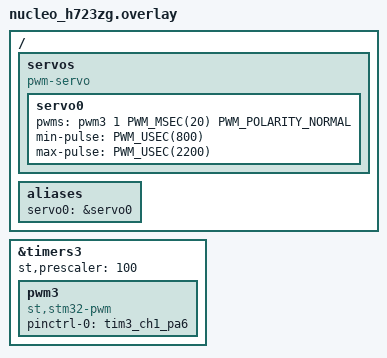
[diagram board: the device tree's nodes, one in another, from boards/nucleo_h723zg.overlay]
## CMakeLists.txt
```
cmake_minimum_required(VERSION 3.20.0)

set(CMAKE_CXX_STANDARD 11)
set(CMAKE_C_STANDARD 11)

# For the compile_commands.json file
set(CMAKE_EXPORT_COMPILE_COMMANDS ON)

# Set the Kconfig file
set(CONF_FILE "prj.conf")

find_package(Zephyr REQUIRED HINTS $ENV{ZEPHYR_BASE})
project(test)

add_subdirectory(${CMAKE_CURRENT_SOURCE_DIR}/lib/drivetrain)

target_sources(app PRIVATE ${CMAKE_CURRENT_SOURCE_DIR}/src/main.c)
```

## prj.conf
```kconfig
# Periphirals
CONFIG_PWM=y
CONFIG_SHELL=y

# CONFIG_PRINTK=y
# CONFIG_STDOUT_CONSOLE=y

# Logging
CONFIG_LOG=y
CONFIG_LOG_MODE_IMMEDIATE=y
CONFIG_LOG_DEFAULT_LEVEL=3
# CONFIG_PWM_LOG_LEVEL_DBG=y
# CONFIG_LOG_PRINTK=y

# Disable optimizations for debugging
CONFIG_DEBUG_OPTIMIZATIONS=y

# Thread aware debugging
CONFIG_THREAD_NAME=y
CONFIG_SEGGER_SYSTEMVIEW=y
CONFIG_USE_SEGGER_RTT=y
CONFIG_TRACING=y
CONFIG_DEBUG_THREAD_INFO=y
CONFIG_DEBUG_INFO=y

# Enable for post-mortem tracing
# NOTE: Recent versions of SEGGER Systemview come with incomplete API translation table for Zephyr
# To fix it: cp ZEPHYR_BASE/subsys/tracing/sysview/SYSVIEW_Zephyr.txt ~/.config/SEGGER/
CONFIG_SEGGER_SYSVIEW_POST_MORTEM_MODE=y
```

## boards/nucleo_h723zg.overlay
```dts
/ {
	servos {
		compatible = "pwm-servo";
		servo0: servo0 {
			pwms = <&pwm3 1 PWM_MSEC(20) PWM_POLARITY_NORMAL>;
			min-pulse = <PWM_USEC(800)>;
			max-pulse = <PWM_USEC(2200)>;
		};
	};

	aliases {
		servo0 = &servo0;
	};
};

&timers3 {
	status = "okay";
	// Timer at 275 MHz.
	st,prescaler = <100>;

	pwm3: pwm3 {
		compatible = "st,stm32-pwm";
		status = "okay";
		#pwm-cells = <0x3>;
		pinctrl-0 = <&tim3_ch1_pa6>;
		pinctrl-names = "default";
	};
};
```

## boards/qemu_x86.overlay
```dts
/ {
	pwmleds {
		compatible = "pwm-leds";

		red_pwm_led: red_pwm_led {
			pwms = <&pwm12 1 PWM_MSEC(20) PWM_POLARITY_NORMAL>;
			label = "User LD3 - PWM12";
		};
	};

    aliases {
        pwm-led0 = &red_pwm_led;
    };
};

&timers12 {
	st,prescaler = <10000>;
	status = "okay";

	pwm12: pwm {
		status = "okay";
		pinctrl-0 = <&tim12_ch1_pb14>;
		pinctrl-names = "default";
	};
};
```

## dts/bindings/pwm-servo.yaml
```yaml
description: |
  General Servo Motor PWM Bindings

compatible: pwm-servo

child-binding:
  description: PWM child node
  properties:
    pwms:
      required: true
      type: phandle-array

    min-pulse:
      type: int
      default: 800
      description: |
        Minimum pulse width in microseconds. This is the pulse width
        corresponding to the minimum servo position.

    max-pulse:
      type: int
      default: 2200
      description: |
        Maximum pulse width in microseconds. This is the pulse width
        corresponding to the maximum servo position.
```

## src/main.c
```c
// Copyright 2023 Jasper Jonker
#include <zephyr/kernel.h>
#include <zephyr/sys/printk.h>
#include <zephyr/device.h>
#include <zephyr/drivers/pwm.h>
#include <zephyr/drivers/uart.h>
#include <zephyr/logging/log.h>
#include "../lib/drivetrain/drivetrain.h"

/* LOG Module */
LOG_MODULE_REGISTER(main);

/* Function prototypes */
int8_t init_pwm_led(uint32_t period, uint32_t pulse_width);

/* PWM LED */
static const struct pwm_dt_spec pwm_led0 = PWM_DT_SPEC_GET(DT_ALIAS(pwm_led0));

// ------------------------------------------------
// Initialize PWM LED
// ------------------------------------------------
int8_t init_pwm_led(uint32_t period, uint32_t pulse_width) {
    if (!device_is_ready(pwm_led0.dev)) {
        LOG_ERR("Cannot find PWM LED device!\n");
        return -1;
    } else {
        LOG_INF("PWM LED device found: %s\r\n", pwm_led0.dev->name);
    }

    int ret = pwm_set_dt(&pwm_led0, period, pulse_width);
    if (ret < 0) {
        LOG_ERR("Error %d: failed to set pulse width\r\n", ret);
        return -1;
    } else {
        LOG_INF("PWM set!\r\n");
    }

    return 0;
}


int main(void) {
    LOG_INF("Booting...\r\n");

    init_pwm_led((uint32_t)2e9, (uint32_t)1e9);
    init_drivetrain();

    /*
    while (1) {
        k_sleep(K_SECONDS(5));
        // ramp_pwm(PWM_USEC(1000), PWM_USEC(2100), PWM_USEC(10));
        set_pulse_width_drivetrain(PWM_USEC(1000));
        k_sleep(K_SECONDS(5));
        // ramp_pwm(PWM_USEC(2000), PWM_USEC(900), PWM_USEC(10));
        set_pulse_width_drivetrain(PWM_USEC(2000));
    }
    */
    LOG_INF("Booting...[DONE]\r\n");

    // while (1) {
    //     ramp_pwm_drivetrain(PWM_USEC(1000), PWM_USEC(2000));
    //     ramp_pwm_drivetrain(PWM_USEC(2000), PWM_USEC(1000));
    // }


    while (1) {
        k_sleep(K_SECONDS(1));
    }

    return 0;
}
```

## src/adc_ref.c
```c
/*
 * Copyright (c) 2020 Libre Solar Technologies GmbH
 *
 * SPDX-License-Identifier: Apache-2.0
 */

#include <inttypes.h>
#include <stddef.h>
#include <stdint.h>

#include <zephyr/device.h>
#include <zephyr/devicetree.h>
#include <zephyr/drivers/adc.h>
#include <zephyr/kernel.h>
#include <zephyr/sys/printk.h>
#include <zephyr/sys/util.h>

#if !DT_NODE_EXISTS(DT_PATH(zephyr_user)) || \
    !DT_NODE_HAS_PROP(DT_PATH(zephyr_user), io_channels)
#error "No suitable devicetree overlay specified"
#endif

#define DT_SPEC_AND_COMMA(node_id, prop, idx) ADC_DT_SPEC_GET_BY_IDX(node_id, idx),

/* Data of ADC io-channels specified in devicetree. */
static const struct adc_dt_spec adc_channels[] = {
    DT_FOREACH_PROP_ELEM(DT_PATH(zephyr_user), io_channels,
        DT_SPEC_AND_COMMA)
};

int main(void) {
    int err;
    uint32_t count = 0;
    uint16_t buf;
    struct adc_sequence sequence = {
        .buffer = &buf,
        /* buffer size in bytes, not number of samples */
        .buffer_size = sizeof(buf),
    };

    /* Configure channels individually prior to sampling. */
    for (size_t i = 0U; i < ARRAY_SIZE(adc_channels); i++) {
        if (!device_is_ready(adc_channels[i].dev)) {
            printk("ADC controller device %s not ready\n", adc_channels[i].dev->name);
            return 0;
        }

        err = adc_channel_setup_dt(&adc_channels[i]);
        if (err < 0) {
            printk("Could not setup channel #%d (%d)\n", i, err);
            return 0;
        }
    }

    while (1) {
        printk("ADC reading[%u]:\n", count++);
        for (size_t i = 0U; i < ARRAY_SIZE(adc_channels); i++) {
            int32_t val_mv;

            printk("- %s, channel %d: ",
                adc_channels[i].dev->name,
                adc_channels[i].channel_id);

            (void)adc_sequence_init_dt(&adc_channels[i], &sequence);

            err = adc_read(adc_channels[i].dev, &sequence);
            if (err < 0) {
                printk("Could not read (%d)\n", err);
                continue;
            }

            /*
             * If using differential mode, the 16 bit value
             * in the ADC sample buffer should be a signed 2's
             * complement value.
             */
            if (adc_channels[i].channel_cfg.differential) {
                val_mv = (int32_t)((int16_t)buf);
            } else {
                val_mv = (int32_t)buf;
            }
            printk("%" PRId32, val_mv);
            err = adc_raw_to_millivolts_dt(&adc_channels[i], &val_mv);
            /* conversion to mV may not be supported, skip if not */
            if (err < 0) {
                printk(" (value in mV not available)\n");
            } else {
                printk(" = %" PRId32 " mV\n", val_mv);
            }
        }

        k_sleep(K_MSEC(1000));
    }
    return 0;
}
```

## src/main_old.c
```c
// Copyright 2023 Jasper Jonker
#include <zephyr/kernel.h>
#include <zephyr/sys/printk.h>
#include <zephyr/device.h>
#include <zephyr/drivers/pwm.h>
#include <zephyr/drivers/uart.h>
#include <zephyr/drivers/adc.h>
#include <string.h>  // memset
#include <stdio.h>

#include <zephyr/logging/log.h>
LOG_MODULE_REGISTER(main);

#if !DT_NODE_EXISTS(DT_PATH(zephyr_user)) || \
    !DT_NODE_HAS_PROP(DT_PATH(zephyr_user), io_channels)
#error "No suitable devicetree overlay specified"
#endif

#define DT_SPEC_AND_COMMA(node_id, prop, idx) ADC_DT_SPEC_GET_BY_IDX(node_id, idx),

/* Data of ADC io-channels specified in devicetree. */
static const struct adc_dt_spec adc_channels[] = {
    DT_FOREACH_PROP_ELEM(DT_PATH(zephyr_user), io_channels, DT_SPEC_AND_COMMA)
};

// #define BUFFER_SIZE                 10000
// #define BAD_ANALOG_READ             -1

/* Thread settings */
#define STACKSIZE                   1024
#define PRIORITY                    7

/* Console UART settings*/
#define CONSOLE_UART_NAME           DT_NODELABEL(usart3)

/* Get UART device */
#if DT_NODE_HAS_STATUS(CONSOLE_UART_NAME, okay)
const struct device *const uart_dev = DEVICE_DT_GET(CONSOLE_UART_NAME);
#else
#error "UART is disabled"
#endif

static struct k_mutex uart_mutex;

/* ADC Buffer */
static uint16_t adc_buf;
static struct k_fifo adc_fifo;

static struct adc_sequence sequence = {
    .buffer = &adc_buf,
    /* buffer size in bytes, not number of samples */
    .buffer_size = sizeof(adc_buf),
};

// struct k_poll_signal async_sig;

/* Function prototypes */
void init_adc(void);
void print_adc_readings(void);
void print_uart3(char *buf);
int8_t init_pwm_led(uint32_t period, uint32_t pulse_width);


/* Initialize the ADC device */
void init_adc(void) {
    for (size_t i = 0U; i < ARRAY_SIZE(adc_channels); i++) {
        if (!device_is_ready(adc_channels[i].dev)) {
            printk("ADC controller device %s not ready\r\r\n", adc_channels[i].dev->name);
            return;
        }

        int err = adc_channel_setup_dt(&adc_channels[i]);
        if (err < 0) {
            printk("Could not setup channel #%d (%d)\r\n", i, err);
            return;
        }
    }

    if (!device_is_ready(uart_dev)) {
        char buf[50];
        snprintf(buf, sizeof(buf), "UART device %s not ready\r\n", uart_dev->name);
        print_uart3(buf);
        return;
    }

    // Setup async signal
    // k_poll_signal_init(&async_sig);
    // struct k_poll_event async_event =
    //     K_POLL_EVENT_INITIALIZER(K_POLL_TYPE_SIGNAL, K_POLL_MODE_NOTIFY_ONLY, &async_sig);

    // Clean buffer
    // memset(sample_buffer, 0, sizeof(sample_buffer));

    print_uart3("ADC setup done\r\n");
    // printk("ADC setup done!\r\n");

    int err;
    int32_t val_mv;
    while (1) {
        for (int i = 0U; i < ARRAY_SIZE(adc_channels); i++) {
            adc_sequence_init_dt(&adc_channels[i], &sequence);

            err = adc_read(adc_channels[i].dev, &sequence);
            if (err < 0) {
                print_uart3("ADC read failed\r\n");
            }

            if (adc_channels[i].channel_cfg.differential) {
                val_mv = (int32_t)((int16_t)adc_buf);
            } else {
                val_mv = (int32_t)adc_buf;
            }

            err = adc_raw_to_millivolts_dt(&adc_channels[i], &val_mv);
            if (err < 0) {
                print_uart3("ADC conversion to milivolt not supported\r\n");
            }

            // printk("Place ADC reading %d in FIFO\r\n", val_mv);
            // Place ADC reading in fifo buffer
            k_fifo_alloc_put(&adc_fifo, &val_mv);
        }
        k_sleep(K_MSEC(1000));
    }

    // bool first_half = true;
    // int half_buffer_size = sizeof(sample_buffer) / 2;

    // Start sampling
    // int err = adc_read_async(adc_dev, &sequence, &async_sig);
    // if (err) {
    //     printk("ADC read failed with code %d!\r\n", err);
    // } else {
    //     printk("ADC read started!\r\n");
    // }

    // while (1) {
    //     k_poll(&async_event, 1, K_FOREVER);

    //     async_event.signal->signaled = 0;
    //     async_event.state = K_POLL_STATE_NOT_READY;

    //     if (first_half) {
    //         send_all_usb(uart_dev,
    //             (uint8_t*)sample_buffer, half_buffer_size);
    //         first_half = false;
    //     } else {
    //         send_all_usb(uart_dev,
    //             ((uint8_t*)sample_buffer) + half_buffer_size, half_buffer_size);
    //         first_half = true;
    //     }
    // }
}

// ------------------------------------------------
// Print ADC values
// ------------------------------------------------
void print_adc_readings(void) {
    int32_t *val_mv;
    // char buffer[50];

    while (1) {
        val_mv = k_fifo_get(&adc_fifo, K_FOREVER);
        // Fix this for all channels
        // snprintf(buffer, sizeof(buffer), "ADC read (channel %d): %d mV\r\n", adc_channels[0].channel_id, *val_mv);
        LOG_INF("ADC read (channel %d): %d mV", adc_channels[0].channel_id, *val_mv);
        k_sleep(K_MSEC(1000));
    }
}

// ------------------------------------------------
// Write to uart3
// ------------------------------------------------
void print_uart3(char *buf) {
    int msg_len = strlen(buf);

    k_mutex_lock(&uart_mutex, K_FOREVER);
    for (int i = 0; i < msg_len; i++) {
        uart_poll_out(uart_dev, buf[i]);
    }
    k_mutex_unlock(&uart_mutex);
}

// ------------------------------------------------
// Initialize PWM
// ------------------------------------------------
int8_t init_pwm_led(uint32_t period, uint32_t pulse_width) {
    static const struct pwm_dt_spec pwm_led0 = PWM_DT_SPEC_GET(DT_ALIAS(pwm_led0));
    if (!device_is_ready(pwm_led0.dev)) {
        printk("Cannot find PWM device!\n");
        return -1;
    } else {
        printk("PWM device found: %s\r\n", pwm_led0.dev->name);
    }

    int ret = pwm_set_dt(&pwm_led0, period, pulse_width);
    if (ret < 0) {
        printk("Error %d: failed to set pulse width\r\n", ret);
        return -1;
    } else {
        printk("PWM set!\r\n");
    }

    return 0;
}

K_THREAD_DEFINE(adc_thread,       STACKSIZE, init_adc,           NULL, NULL, NULL, PRIORITY, 0, 500);
K_THREAD_DEFINE(adc_print_thread, STACKSIZE, print_adc_readings, NULL, NULL, NULL, PRIORITY, 0, 500);

int main(void) {
    LOG_INF("Booting...\r\n");

    k_fifo_init(&adc_fifo);
    k_mutex_init(&uart_mutex);
    init_pwm_led((uint32_t)2e9, (uint32_t)1e9);

    k_sleep(K_MSEC(300));
    LOG_INF("Booting...[DONE]\r\n");

    while (1) {
        k_sleep(K_MSEC(1000));
    }

    return 0;
}
```
